AUTOSAR XML (schema 00044)
package /ComponentTypes
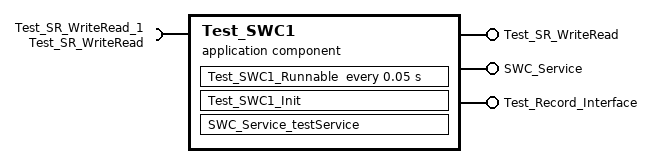
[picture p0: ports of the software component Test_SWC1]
  application sw component type Test_SWC1
    provide port Test_SR_WriteRead: provided-com-specs=[{data-element=DataElement1, init-value=0}, {data-element=DataElement2, init-value=2}], provided-interface=Test_SR_WriteRead
    require port Test_SR_WriteRead_1: required-interface=Test_SR_WriteRead
      required-com-specs:
        data-element=DataElement1, init-value=0
        data-element=DataElement2, filter=data-filter-type=ALWAYS, init-value=1
    provide port SWC_Service: server-com-spec{operation=testService, queue-length=1}, provided-interface=SWC_Service
    provide port Test_Record_Interface: nonqueued-sender-com-spec{data-element=Record, init-value=fields=[ElementConstant:[1, 2, 3], ElementConstant_1:0]}, provided-interface=Test_Record_Interface
    behavior Test_SWC1_InternalBehavior
      init event Test_SWC1_InitEvent: start-on-event=Test_SWC1_Init
      timing event TMT_Test_SWC1_Runnable: start-on-event=Test_SWC1_Runnable, period=0.05
      operation invoked event OIT_SWC_Service_testService_SWC_Service_testService: start-on-event=SWC_Service_testService, operation=SWC_Service.testService
      runnable Test_SWC1_Init
        data-receive-point-by-arguments:
          access REC_Test_SR_WriteRead_1_DataElement1: accessed-variable=Test_SR_WriteRead_1.DataElement1
        data-send-points:
          access SEND_Test_SR_WriteRead_DataElement1: accessed-variable=Test_SR_WriteRead.DataElement1
      runnable Test_SWC1_Runnable: minimum-start-interval=0.05
        data-receive-point-by-arguments:
          access REC_Test_SR_WriteRead_1_DataElement1: accessed-variable=Test_SR_WriteRead_1.DataElement1
          access REC_Test_SR_WriteRead_1_DataElement2: accessed-variable=Test_SR_WriteRead_1.DataElement2
        data-send-points:
          access SEND_Test_SR_WriteRead_DataElement1: accessed-variable=Test_SR_WriteRead.DataElement1
          access SEND_Test_SR_WriteRead_DataElement2: accessed-variable=Test_SR_WriteRead.DataElement2
          access SEND_Test_Record_Interface_Record: accessed-variable=Test_Record_Interface.Record
      runnable SWC_Service_testService
  swc implementation Test_SWC1_Implementation: behavior=Test_SWC1_InternalBehavior
